# nrf5001 register map
Vendor: Nordic Semiconductor; Series: nRF50; File version: 1
CPU: CM0 r0p4, little endian, no MPU, no FPU, 2 interrupt priority bits, 32 interrupts
Registers are 32-bit, read-write, reset 0x0 unless marked. A register's access mark holds for its fields unless they carry their own. Offsets are from the block's base; [hi:lo] are bit positions; 'fields as' and 'values as' point back to an identical list.

## RCOSC32K — 32.768 kHz RC oscillator
Base 0x40027000
0x00 TASKS_CAL wo — Start calibration of LFRC oscillator
  [0] TASKS_CAL
    1=Trigger task
0x04 TASKS_CTSTART wo — Deprecated register - Start calibration timer
  [0] TASKS_CTSTART — Deprecated field - Start calibration timer
    1=Trigger task
0x08 TASKS_CTSTOP wo — Deprecated register - Stop calibration timer
  [0] TASKS_CTSTOP — Deprecated field - Stop calibration timer
    1=Trigger task
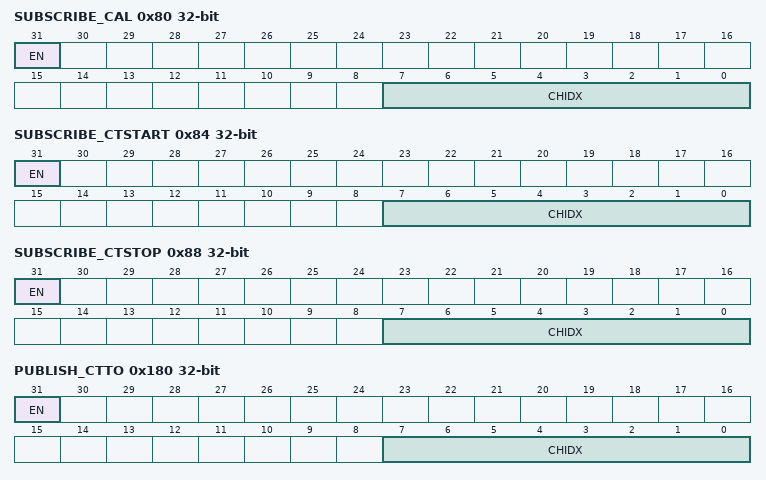
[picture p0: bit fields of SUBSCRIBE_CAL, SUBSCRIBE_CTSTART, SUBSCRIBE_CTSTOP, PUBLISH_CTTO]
0x80 SUBSCRIBE_CAL — Subscribe configuration for task CAL
  [31] EN
    0=Disabled (Disable subscription); 1=Enabled (Enable subscription)
  [7:0] CHIDX — DPPI channel that task CAL will subscribe to
0x84 SUBSCRIBE_CTSTART — Deprecated register - Subscribe configuration for task CTSTART
  [31] EN
    values as SUBSCRIBE_CAL.EN
  [7:0] CHIDX — DPPI channel that task CTSTART will subscribe to
0x88 SUBSCRIBE_CTSTOP — Deprecated register - Subscribe configuration for task CTSTOP
  [31] EN
    values as SUBSCRIBE_CAL.EN
  [7:0] CHIDX — DPPI channel that task CTSTOP will subscribe to
0x100 EVENTS_CTTO — Deprecated register - Calibration timer timeout
  [0] EVENTS_CTTO — Deprecated field - Calibration timer timeout
    0=NotGenerated (Event not generated); 1=Generated (Event generated)
0x104 EVENTS_DONE — Calibration of LFCLK RC oscillator complete event
  [0] EVENTS_DONE
    values as EVENTS_CTTO.EVENTS_CTTO
0x108 EVENTS_CTSTARTED — Deprecated register - Calibration timer started
  [0] EVENTS_CTSTARTED — Deprecated field - Calibration timer started
    values as EVENTS_CTTO.EVENTS_CTTO
0x10C EVENTS_CTSTOPPED — Deprecated register - Calibration timer stopped
  [0] EVENTS_CTSTOPPED — Deprecated field - Calibration timer stopped
    values as EVENTS_CTTO.EVENTS_CTTO
0x180 PUBLISH_CTTO — Deprecated register - Publish configuration for event CTTO
  [31] EN
    0=Disabled (Disable publishing); 1=Enabled (Enable publishing)
  [7:0] CHIDX — DPPI channel that event CTTO will publish to
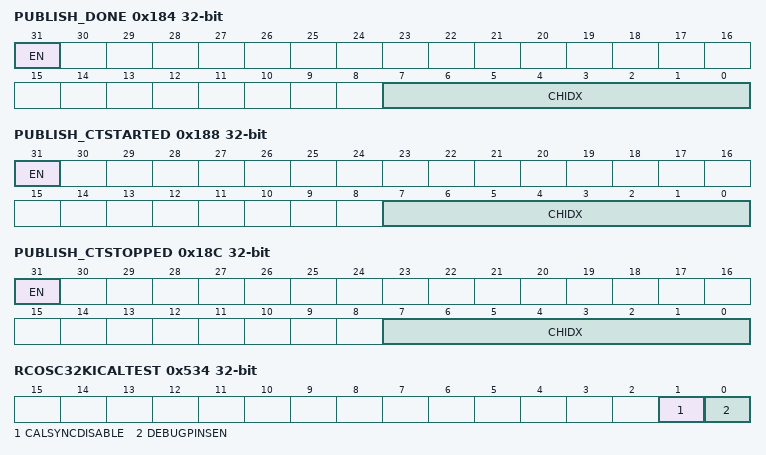
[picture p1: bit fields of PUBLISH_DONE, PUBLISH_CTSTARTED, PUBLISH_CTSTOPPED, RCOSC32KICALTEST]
0x184 PUBLISH_DONE — Publish configuration for event DONE
  [31] EN
    values as PUBLISH_CTTO.EN
  [7:0] CHIDX — DPPI channel that event DONE will publish to
0x188 PUBLISH_CTSTARTED — Deprecated register - Publish configuration for event CTSTARTED
  [31] EN
    values as PUBLISH_CTTO.EN
  [7:0] CHIDX — DPPI channel that event CTSTARTED will publish to
0x18C PUBLISH_CTSTOPPED — Deprecated register - Publish configuration for event CTSTOPPED
  [31] EN
    values as PUBLISH_CTTO.EN
  [7:0] CHIDX — DPPI channel that event CTSTOPPED will publish to
0x420 RCOSC32KIFINE ro — Fine calibration read value for 32.768 kHz RC oscillator
  [9:0] RCOSC32KIFINE
0x424 RCOSC32KICOARSE ro — Coarse calibration read value for 32.768 kHz RC oscillator
  [5:0] RCOSC32KICOARSE
0x534 RCOSC32KICALTEST — 32.768 kHz RC oscillator calibration debug register NOTE: This register should not be written to while the RCOSC source is running.
  [1] CALSYNCDISABLE — Disable calSync auto-calibration
    1=Disabled (calSync auto-calibration disabled); 0=Enabled (calSync auto-calibration enabled)
  [0] DEBUGPINSEN — Enable debug pins: calSync on P0.8 (input); ck32Ki on P0.13 (output); rcosc32KiCalib on P0.19 (output)
    0=Disabled (Pins in normal operation); 1=Enabled (Pins mapped for debug)
0x538 CTIV — Deprecated register - Calibration timer interval NOTE: This register should not be written to while the calibration timer is running.
  [6:0] CTIV — Calibration timer interval in multiple of 0.25 seconds. Range: 0.25 seconds to 31.75 seconds.
0x53C RCOSC32KICALLENGTH reset 0x2 — 32kHz RC oscillator calibration length This value is read from FICR
  [2:0] RCOSC32KICALLENGTH — 32kHz RC oscillator calibration length in number of cycles
    0=N64 (64 cycles); 1=N128 (128 cycles); 2=N256 (256 cycles); 3=N512 (512 cycles)
0x540 RCOSC32KICOARSEIN — RCOSC coarse calibration input This value is read from FICR
  [5:0] RCOSC32KICOARSEIN — RCOSC coarse calibration input
0x54C RCOSC32KICABD — Comparator adaptive biasing disable
  [0] CABD — Disables comparator adaptive biasing
    0=Disabled; 1=Enabled
0x584 ATECLOCK — Analog test bus control for clock modules
  [0] RCOSC32K — Connect or disconnect 32.768 kHz RC oscillator to analog test bus
    0=Disconnected; 1=Connected (Connect internal regulator output to ATB0)
0x5B4 LFRCMODE — LFRC mode configuration
  [0] MODE — Set LFRC mode
    0=Normal mode; 1=ULP (Deprecated enumerator - Ultra-low power mode (ULP))
0x5B8 LFULP32KICOARSEIN — Deprecated register - LFULP coarse calibration input This value is read from FICR
  [5:0] LFULP32KICOARSE — LFULP coarse calibration input
0x5BC LFULP32KICALLENGTH — Deprecated register - 32kHz LFULP RC oscillator calibration length This value is read from FICR
  [2:0] LFULP32KICALLENGTH — 32kHz ULP RC oscillator calibration length in number of cycles
    values as RCOSC32KICALLENGTH.RCOSC32KICALLENGTH
0xBFC DISABLERCOSC32KIPOWERUPCONTROL — Backdoor for disabling Rcosc32KiPowerUpControl module in Rcosc32KiGenerator.
  [0] Disable — Disable Rcosc32KiPowerUpControl.
    0=Enabled (Rcosc32KiPowerUpControl is enabled.); 1=Disabled (Rcosc32KiPowerUpControl is disabled.)
